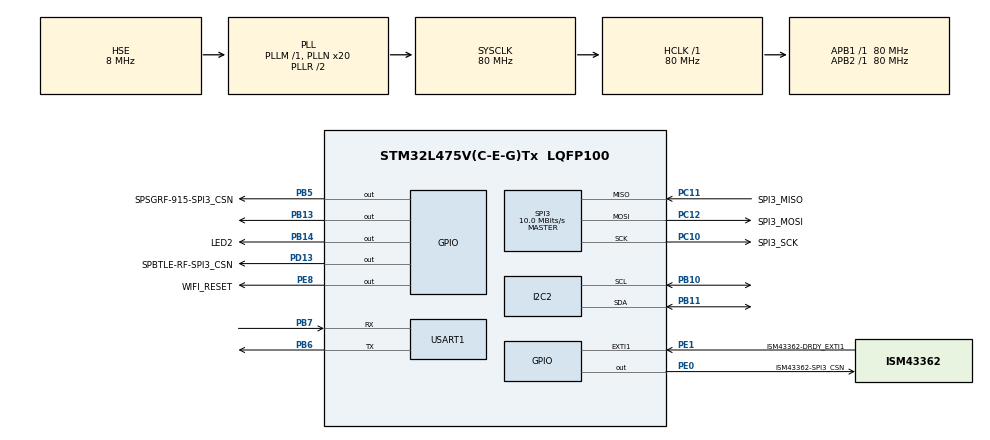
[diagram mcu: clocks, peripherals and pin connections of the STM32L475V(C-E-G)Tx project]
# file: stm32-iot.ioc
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I2C2.Timing=0x10909CEC
Mcu.Family=STM32L4
Mcu.Name=STM32L475V(C-E-G)Tx
Mcu.Package=LQFP100
NVIC.EXTI1_IRQn=true\:0\:0\:false\:false\:true\:true\:true
NVIC.PriorityGroup=NVIC_PRIORITYGROUP_4
NVIC.SPI3_IRQn=true\:0\:0\:false\:false\:true\:true\:true
PA13\ (JTMS-SWDIO).Mode=Serial_Wire
PA13\ (JTMS-SWDIO).Signal=SYS_JTMS-SWDIO
PA14\ (JTCK-SWCLK).Mode=Serial_Wire
PA14\ (JTCK-SWCLK).Signal=SYS_JTCK-SWCLK
PB10.Mode=I2C
PB10.Signal=I2C2_SCL
PB11.Mode=I2C
PB11.Signal=I2C2_SDA
PB13.Signal=GPIO_Output
PB14.GPIO_Label=LED2
PB14.Signal=GPIO_Output
PB5.GPIO_Label=SPSGRF-915-SPI3_CSN
PB5.Signal=GPIO_Output
PB6.Mode=Asynchronous
PB6.Signal=USART1_TX
PB7.Mode=Asynchronous
PB7.Signal=USART1_RX
PC10.GPIO_Label=SPI3_SCK
PC10.Mode=Full_Duplex_Master
PC10.Signal=SPI3_SCK
PC11.GPIO_Label=SPI3_MISO
PC11.Mode=Full_Duplex_Master
PC11.Signal=SPI3_MISO
PC12.GPIO_Label=SPI3_MOSI
PC12.Mode=Full_Duplex_Master
PC12.Signal=SPI3_MOSI
PD13.GPIO_Label=SPBTLE-RF-SPI3_CSN
PD13.Signal=GPIO_Output
PE0.GPIO_Label=ISM43362-SPI3_CSN
PE0.Signal=GPIO_Output
PE1.GPIO_Label=ISM43362-DRDY_EXTI1
PE1.GPIO_ModeDefaultEXTI=GPIO_MODE_IT_RISING
PE1.Signal=GPXTI1
PE8.GPIO_Label=WIFI_RESET
PE8.GPIO_Speed=GPIO_SPEED_FREQ_HIGH
PE8.Signal=GPIO_Output
PH0-OSC_IN\ (PH0).Mode=HSE-External-Oscillator
PH0-OSC_IN\ (PH0).Signal=RCC_OSC_IN
PH1-OSC_OUT\ (PH1).Mode=HSE-External-Oscillator
PH1-OSC_OUT\ (PH1).Signal=RCC_OSC_OUT
ProjectManager.HeapSize=0x200
ProjectManager.StackSize=0x400
ProjectManager.TargetToolchain=STM32CubeIDE
RCC.ADCFreq_Value=32000000
RCC.AHBFreq_Value=80000000
RCC.APB1Freq_Value=80000000
RCC.APB1TimFreq_Value=80000000
RCC.APB2Freq_Value=80000000
RCC.APB2TimFreq_Value=80000000
RCC.CortexFreq_Value=80000000
RCC.HCLKFreq_Value=80000000
RCC.HSE_VALUE=8000000
RCC.HSI_VALUE=16000000
RCC.LSE_VALUE=32768
RCC.MSI_VALUE=4000000
RCC.PLLN=20
RCC.PLLSourceVirtual=RCC_PLLSOURCE_HSE
RCC.SYSCLKFreq_VALUE=80000000
RCC.SYSCLKSource=RCC_SYSCLKSOURCE_PLLCLK
RCC.USBFreq_Value=32000000
RCC.VCOOutputFreq_Value=160000000
SPI3.BaudRatePrescaler=SPI_BAUDRATEPRESCALER_8
SPI3.CalculateBaudRate=10.0 MBits/s
SPI3.DataSize=SPI_DATASIZE_16BIT
SPI3.Direction=SPI_DIRECTION_2LINES
SPI3.Mode=SPI_MODE_MASTER
SPI3.VirtualType=VM_MASTER
USART1.VirtualMode-Asynchronous=VM_ASYNC
board=custom

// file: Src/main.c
/* USER CODE BEGIN Header */
/**
  ******************************************************************************
  * @file           : main.c
  * @brief          : Main program body
  ******************************************************************************
  * @attention
  *
  * <h2><center>&copy; Copyright (c) 2019 STMicroelectronics.
  * All rights reserved.</center></h2>
  *
  * This software component is licensed by ST under BSD 3-Clause license,
  * the "License"; You may not use this file except in compliance with the
  * License. You may obtain a copy of the License at:
  *                        opensource.org/licenses/BSD-3-Clause
  *
  ******************************************************************************
  */
/* USER CODE END Header */

#include "main.h"

/* USER CODE BEGIN Includes */
#include "setup_hw.h"
/* USER CODE END Includes */

I2C_HandleTypeDef hi2c2;

SPI_HandleTypeDef hspi3;

UART_HandleTypeDef huart1;

void SystemClock_Config(void);
static void MX_GPIO_Init(void);
static void MX_I2C2_Init(void);
static void MX_USART1_UART_Init(void);
static void MX_SPI3_Init(void);

int main(void)
{

  /* MCU Configuration--------------------------------------------------------*/

  /* Reset of all peripherals, Initializes the Flash interface and the Systick. */
  HAL_Init();

  /* Configure the system clock */
  SystemClock_Config();

  /* Initialize all configured peripherals */
  MX_GPIO_Init();
  MX_I2C2_Init();
  MX_USART1_UART_Init();
  MX_SPI3_Init();
  /* USER CODE BEGIN 2 */

  Setup_Init();
  /* USER CODE END 2 */

  /* Infinite loop */
  while (1)
  {

  }
}

void SystemClock_Config(void)
{
  RCC_OscInitTypeDef RCC_OscInitStruct = {0};
  RCC_ClkInitTypeDef RCC_ClkInitStruct = {0};
  RCC_PeriphCLKInitTypeDef PeriphClkInit = {0};

  /** Initializes the CPU, AHB and APB busses clocks
  */
  RCC_OscInitStruct.OscillatorType = RCC_OSCILLATORTYPE_HSE;
  RCC_OscInitStruct.HSEState = RCC_HSE_ON;
  RCC_OscInitStruct.PLL.PLLState = RCC_PLL_ON;
  RCC_OscInitStruct.PLL.PLLSource = RCC_PLLSOURCE_HSE;
  RCC_OscInitStruct.PLL.PLLM = 1;
  RCC_OscInitStruct.PLL.PLLN = 20;
  RCC_OscInitStruct.PLL.PLLP = RCC_PLLP_DIV7;
  RCC_OscInitStruct.PLL.PLLQ = RCC_PLLQ_DIV2;
  RCC_OscInitStruct.PLL.PLLR = RCC_PLLR_DIV2;
  if (HAL_RCC_OscConfig(&RCC_OscInitStruct) != HAL_OK)
  {
    Error_Handler();
  }
  /** Initializes the CPU, AHB and APB busses clocks
  */
  RCC_ClkInitStruct.ClockType = RCC_CLOCKTYPE_HCLK|RCC_CLOCKTYPE_SYSCLK
                              |RCC_CLOCKTYPE_PCLK1|RCC_CLOCKTYPE_PCLK2;
  RCC_ClkInitStruct.SYSCLKSource = RCC_SYSCLKSOURCE_PLLCLK;
  RCC_ClkInitStruct.AHBCLKDivider = RCC_SYSCLK_DIV1;
  RCC_ClkInitStruct.APB1CLKDivider = RCC_HCLK_DIV1;
  RCC_ClkInitStruct.APB2CLKDivider = RCC_HCLK_DIV1;

  if (HAL_RCC_ClockConfig(&RCC_ClkInitStruct, FLASH_LATENCY_4) != HAL_OK)
  {
    Error_Handler();
  }
  PeriphClkInit.PeriphClockSelection = RCC_PERIPHCLK_USART1|RCC_PERIPHCLK_I2C2;
  PeriphClkInit.Usart1ClockSelection = RCC_USART1CLKSOURCE_PCLK2;
  PeriphClkInit.I2c2ClockSelection = RCC_I2C2CLKSOURCE_PCLK1;
  if (HAL_RCCEx_PeriphCLKConfig(&PeriphClkInit) != HAL_OK)
  {
    Error_Handler();
  }
  /** Configure the main internal regulator output voltage
  */
  if (HAL_PWREx_ControlVoltageScaling(PWR_REGULATOR_VOLTAGE_SCALE1) != HAL_OK)
  {
    Error_Handler();
  }
}

static void MX_I2C2_Init(void)
{

  hi2c2.Instance = I2C2;
  hi2c2.Init.Timing = 0x10909CEC;
  hi2c2.Init.OwnAddress1 = 0;
  hi2c2.Init.AddressingMode = I2C_ADDRESSINGMODE_7BIT;
  hi2c2.Init.DualAddressMode = I2C_DUALADDRESS_DISABLE;
  hi2c2.Init.OwnAddress2 = 0;
  hi2c2.Init.OwnAddress2Masks = I2C_OA2_NOMASK;
  hi2c2.Init.GeneralCallMode = I2C_GENERALCALL_DISABLE;
  hi2c2.Init.NoStretchMode = I2C_NOSTRETCH_DISABLE;
  if (HAL_I2C_Init(&hi2c2) != HAL_OK)
  {
    Error_Handler();
  }
  /** Configure Analogue filter
  */
  if (HAL_I2CEx_ConfigAnalogFilter(&hi2c2, I2C_ANALOGFILTER_ENABLE) != HAL_OK)
  {
    Error_Handler();
  }
  /** Configure Digital filter
  */
  if (HAL_I2CEx_ConfigDigitalFilter(&hi2c2, 0) != HAL_OK)
  {
    Error_Handler();
  }

}

static void MX_SPI3_Init(void)
{

  /* SPI3 parameter configuration*/
  hspi3.Instance = SPI3;
  hspi3.Init.Mode = SPI_MODE_MASTER;
  hspi3.Init.Direction = SPI_DIRECTION_2LINES;
  hspi3.Init.DataSize = SPI_DATASIZE_16BIT;
  hspi3.Init.CLKPolarity = SPI_POLARITY_LOW;
  hspi3.Init.CLKPhase = SPI_PHASE_1EDGE;
  hspi3.Init.NSS = SPI_NSS_SOFT;
  hspi3.Init.BaudRatePrescaler = SPI_BAUDRATEPRESCALER_8;
  hspi3.Init.FirstBit = SPI_FIRSTBIT_MSB;
  hspi3.Init.TIMode = SPI_TIMODE_DISABLE;
  hspi3.Init.CRCCalculation = SPI_CRCCALCULATION_DISABLE;
  hspi3.Init.CRCPolynomial = 7;
  hspi3.Init.CRCLength = SPI_CRC_LENGTH_DATASIZE;
  hspi3.Init.NSSPMode = SPI_NSS_PULSE_ENABLE;
  if (HAL_SPI_Init(&hspi3) != HAL_OK)
  {
    Error_Handler();
  }

}

static void MX_USART1_UART_Init(void)
{

  huart1.Instance = USART1;
  huart1.Init.BaudRate = 115200;
  huart1.Init.WordLength = UART_WORDLENGTH_8B;
  huart1.Init.StopBits = UART_STOPBITS_1;
  huart1.Init.Parity = UART_PARITY_NONE;
  huart1.Init.Mode = UART_MODE_TX_RX;
  huart1.Init.HwFlowCtl = UART_HWCONTROL_NONE;
  huart1.Init.OverSampling = UART_OVERSAMPLING_16;
  huart1.Init.OneBitSampling = UART_ONE_BIT_SAMPLE_DISABLE;
  huart1.AdvancedInit.AdvFeatureInit = UART_ADVFEATURE_NO_INIT;
  if (HAL_UART_Init(&huart1) != HAL_OK)
  {
    Error_Handler();
  }

}

static void MX_GPIO_Init(void)
{
  GPIO_InitTypeDef GPIO_InitStruct = {0};

  /* GPIO Ports Clock Enable */
  __HAL_RCC_GPIOH_CLK_ENABLE();
  __HAL_RCC_GPIOE_CLK_ENABLE();
  __HAL_RCC_GPIOB_CLK_ENABLE();
  __HAL_RCC_GPIOD_CLK_ENABLE();
  __HAL_RCC_GPIOA_CLK_ENABLE();
  __HAL_RCC_GPIOC_CLK_ENABLE();

  /*Configure GPIO pin Output Level */
  HAL_GPIO_WritePin(GPIOE, WIFI_RESET_Pin|ISM43362_SPI3_CSN_Pin, GPIO_PIN_RESET);

  /*Configure GPIO pin Output Level */
  HAL_GPIO_WritePin(GPIOB, GPIO_PIN_13|LED2_Pin|SPSGRF_915_SPI3_CSN_Pin, GPIO_PIN_RESET);

  /*Configure GPIO pin Output Level */
  HAL_GPIO_WritePin(SPBTLE_RF_SPI3_CSN_GPIO_Port, SPBTLE_RF_SPI3_CSN_Pin, GPIO_PIN_RESET);

  /*Configure GPIO pin : WIFI_RESET_Pin */
  GPIO_InitStruct.Pin = WIFI_RESET_Pin;
  GPIO_InitStruct.Mode = GPIO_MODE_OUTPUT_PP;
  GPIO_InitStruct.Pull = GPIO_NOPULL;
  GPIO_InitStruct.Speed = GPIO_SPEED_FREQ_HIGH;
  HAL_GPIO_Init(WIFI_RESET_GPIO_Port, &GPIO_InitStruct);

  /*Configure GPIO pins : PB13 LED2_Pin SPSGRF_915_SPI3_CSN_Pin */
  GPIO_InitStruct.Pin = GPIO_PIN_13|LED2_Pin|SPSGRF_915_SPI3_CSN_Pin;
  GPIO_InitStruct.Mode = GPIO_MODE_OUTPUT_PP;
  GPIO_InitStruct.Pull = GPIO_NOPULL;
  GPIO_InitStruct.Speed = GPIO_SPEED_FREQ_LOW;
  HAL_GPIO_Init(GPIOB, &GPIO_InitStruct);

  /*Configure GPIO pin : SPBTLE_RF_SPI3_CSN_Pin */
  GPIO_InitStruct.Pin = SPBTLE_RF_SPI3_CSN_Pin;
  GPIO_InitStruct.Mode = GPIO_MODE_OUTPUT_PP;
  GPIO_InitStruct.Pull = GPIO_NOPULL;
  GPIO_InitStruct.Speed = GPIO_SPEED_FREQ_LOW;
  HAL_GPIO_Init(SPBTLE_RF_SPI3_CSN_GPIO_Port, &GPIO_InitStruct);

  /*Configure GPIO pin : ISM43362_SPI3_CSN_Pin */
  GPIO_InitStruct.Pin = ISM43362_SPI3_CSN_Pin;
  GPIO_InitStruct.Mode = GPIO_MODE_OUTPUT_PP;
  GPIO_InitStruct.Pull = GPIO_NOPULL;
  GPIO_InitStruct.Speed = GPIO_SPEED_FREQ_LOW;
  HAL_GPIO_Init(ISM43362_SPI3_CSN_GPIO_Port, &GPIO_InitStruct);

  /*Configure GPIO pin : ISM43362_DRDY_EXTI1_Pin */
  GPIO_InitStruct.Pin = ISM43362_DRDY_EXTI1_Pin;
  GPIO_InitStruct.Mode = GPIO_MODE_IT_RISING;
  GPIO_InitStruct.Pull = GPIO_NOPULL;
  HAL_GPIO_Init(ISM43362_DRDY_EXTI1_GPIO_Port, &GPIO_InitStruct);

  /* EXTI interrupt init*/
  HAL_NVIC_SetPriority(EXTI1_IRQn, 0, 0);
  HAL_NVIC_EnableIRQ(EXTI1_IRQn);

}

void Error_Handler(void)
{
}

/************************ (C) COPYRIGHT STMicroelectronics *****END OF FILE****/
